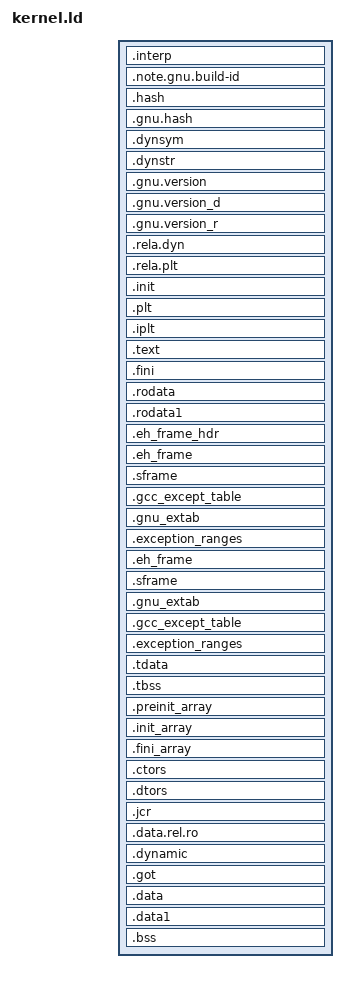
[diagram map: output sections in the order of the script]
OUTPUT_FORMAT("elf32-m68k", "elf32-m68k", "elf32-m68k")
OUTPUT_ARCH(m68k)

ENTRY(_start)
SECTIONS
{
  . = 0x80000000 + SIZEOF_HEADERS;

  .interp         : { *(.interp) }
  .note.gnu.build-id  : { *(.note.gnu.build-id) }
  .hash           : { *(.hash) }
  .gnu.hash       : { *(.gnu.hash) }
  .dynsym         : { *(.dynsym) }
  .dynstr         : { *(.dynstr) }
  .gnu.version    : { *(.gnu.version) }
  .gnu.version_d  : { *(.gnu.version_d) }
  .gnu.version_r  : { *(.gnu.version_r) }
  .rela.dyn       :
    {
      *(.rela.init)
      *(.rela.text .rela.text.* .rela.gnu.linkonce.t.*)
      *(.rela.fini)
      *(.rela.rodata .rela.rodata.* .rela.gnu.linkonce.r.*)
      *(.rela.data .rela.data.* .rela.gnu.linkonce.d.*)
      *(.rela.tdata .rela.tdata.* .rela.gnu.linkonce.td.*)
      *(.rela.tbss .rela.tbss.* .rela.gnu.linkonce.tb.*)
      *(.rela.ctors)
      *(.rela.dtors)
      *(.rela.got)
      *(.rela.bss .rela.bss.* .rela.gnu.linkonce.b.*)
      PROVIDE_HIDDEN (__rela_iplt_start = .);
      *(.rela.iplt)
      PROVIDE_HIDDEN (__rela_iplt_end = .);
    }
  .rela.plt       :
    {
      *(.rela.plt)
    }
  .init           :
  {
    KEEP (*(SORT_NONE(.init)))
  } =0x4e714e71
  .plt            : { *(.plt) }
  .iplt           : { *(.iplt) }
  .text           :
  {
    *(.text.unlikely .text.*_unlikely .text.unlikely.*)
    *(.text.exit .text.exit.*)
    *(.text.startup .text.startup.*)
    *(.text.hot .text.hot.*)
    *(SORT(.text.sorted.*))
    *(.text .stub .text.* .gnu.linkonce.t.*)
    /* .gnu.warning sections are handled specially by elf.em.  */
    *(.gnu.warning)
  } =0x4e714e71
  .fini           :
  {
    KEEP (*(SORT_NONE(.fini)))
  } =0x4e714e71
  PROVIDE (__etext = .);
  PROVIDE (_etext = .);
  PROVIDE (etext = .);
  .rodata         : { *(.rodata .rodata.* .gnu.linkonce.r.*) }
  .rodata1        : { *(.rodata1) }
  .eh_frame_hdr   : { *(.eh_frame_hdr) *(.eh_frame_entry .eh_frame_entry.*) }
  .eh_frame       : ONLY_IF_RO { KEEP (*(.eh_frame)) *(.eh_frame.*) }
  .sframe         : ONLY_IF_RO { *(.sframe) *(.sframe.*) }
  .gcc_except_table   : ONLY_IF_RO { *(.gcc_except_table .gcc_except_table.*) }
  .gnu_extab   : ONLY_IF_RO { *(.gnu_extab*) }
  /* These sections are generated by the Sun/Oracle C++ compiler.  */
  .exception_ranges   : ONLY_IF_RO { *(.exception_ranges*) }
  /* Adjust the address for the data segment.  We want to adjust up to
     the same address within the page on the next page up.  */
  . = DATA_SEGMENT_ALIGN (CONSTANT (MAXPAGESIZE), CONSTANT (COMMONPAGESIZE));
  /* Exception handling  */
  .eh_frame       : ONLY_IF_RW { KEEP (*(.eh_frame)) *(.eh_frame.*) }
  .sframe         : ONLY_IF_RW { *(.sframe) *(.sframe.*) }
  .gnu_extab      : ONLY_IF_RW { *(.gnu_extab) }
  .gcc_except_table   : ONLY_IF_RW { *(.gcc_except_table .gcc_except_table.*) }
  .exception_ranges   : ONLY_IF_RW { *(.exception_ranges*) }
  /* Thread Local Storage sections  */
  .tdata	  :
   {
     PROVIDE_HIDDEN (__tdata_start = .);
     *(.tdata .tdata.* .gnu.linkonce.td.*)
   }
  .tbss		  : { *(.tbss .tbss.* .gnu.linkonce.tb.*) *(.tcommon) }
  .preinit_array    :
  {
    PROVIDE_HIDDEN (__preinit_array_start = .);
    KEEP (*(.preinit_array))
    PROVIDE_HIDDEN (__preinit_array_end = .);
  }
  .init_array    :
  {
    PROVIDE_HIDDEN (__init_array_start = .);
    KEEP (*(SORT_BY_INIT_PRIORITY(.init_array.*) SORT_BY_INIT_PRIORITY(.ctors.*)))
    KEEP (*(.init_array EXCLUDE_FILE (*crtbegin.o *crtbegin?.o *crtend.o *crtend?.o ) .ctors))
    PROVIDE_HIDDEN (__init_array_end = .);
  }
  .fini_array    :
  {
    PROVIDE_HIDDEN (__fini_array_start = .);
    KEEP (*(SORT_BY_INIT_PRIORITY(.fini_array.*) SORT_BY_INIT_PRIORITY(.dtors.*)))
    KEEP (*(.fini_array EXCLUDE_FILE (*crtbegin.o *crtbegin?.o *crtend.o *crtend?.o ) .dtors))
    PROVIDE_HIDDEN (__fini_array_end = .);
  }
  .ctors          :
  {
    /* gcc uses crtbegin.o to find the start of
       the constructors, so we make sure it is
       first.  Because this is a wildcard, it
       doesn't matter if the user does not
       actually link against crtbegin.o; the
       linker won't look for a file to match a
       wildcard.  The wildcard also means that it
       doesn't matter which directory crtbegin.o
       is in.  */
    KEEP (*crtbegin.o(.ctors))
    KEEP (*crtbegin?.o(.ctors))
    /* We don't want to include the .ctor section from
       the crtend.o file until after the sorted ctors.
       The .ctor section from the crtend file contains the
       end of ctors marker and it must be last */
    KEEP (*(EXCLUDE_FILE (*crtend.o *crtend?.o ) .ctors))
    KEEP (*(SORT(.ctors.*)))
    KEEP (*(.ctors))
  }
  .dtors          :
  {
    KEEP (*crtbegin.o(.dtors))
    KEEP (*crtbegin?.o(.dtors))
    KEEP (*(EXCLUDE_FILE (*crtend.o *crtend?.o ) .dtors))
    KEEP (*(SORT(.dtors.*)))
    KEEP (*(.dtors))
  }
  .jcr            : { KEEP (*(.jcr)) }
  .data.rel.ro : { *(.data.rel.ro.local* .gnu.linkonce.d.rel.ro.local.*) *(.data.rel.ro .data.rel.ro.* .gnu.linkonce.d.rel.ro.*) }
  .dynamic        : { *(.dynamic) }
  . = DATA_SEGMENT_RELRO_END (0, .);
  .got            : { *(.got.plt) *(.igot.plt) *(.got) *(.igot) }
  .data           :
  {
    *(.data .data.* .gnu.linkonce.d.*)
    SORT(CONSTRUCTORS)
  }
  .data1          : { *(.data1) }
  _edata = .; PROVIDE (edata = .);
  . = .;
  __bss_start = .;
  .bss            :
  {
   *(.dynbss)
   *(.bss .bss.* .gnu.linkonce.b.*)
   *(COMMON)
   /* Align here to ensure that the .bss section occupies space up to
      _end.  Align after .bss to ensure correct alignment even if the
      .bss section disappears because there are no input sections.
      FIXME: Why do we need it? When there is no .bss section, we do not
      pad the .data section.  */
   . = ALIGN(. != 0 ? 32 / 8 : 1);
  }
  . = ALIGN(32 / 8);
  . = SEGMENT_START("ldata-segment", .);
  . = ALIGN(32 / 8);
  _end = .; PROVIDE (end = .);
  . = DATA_SEGMENT_END (.);
  /DISCARD/ : { *(.note.GNU-stack) *(.gnu_debuglink) *(.gnu.lto_*) }
}
